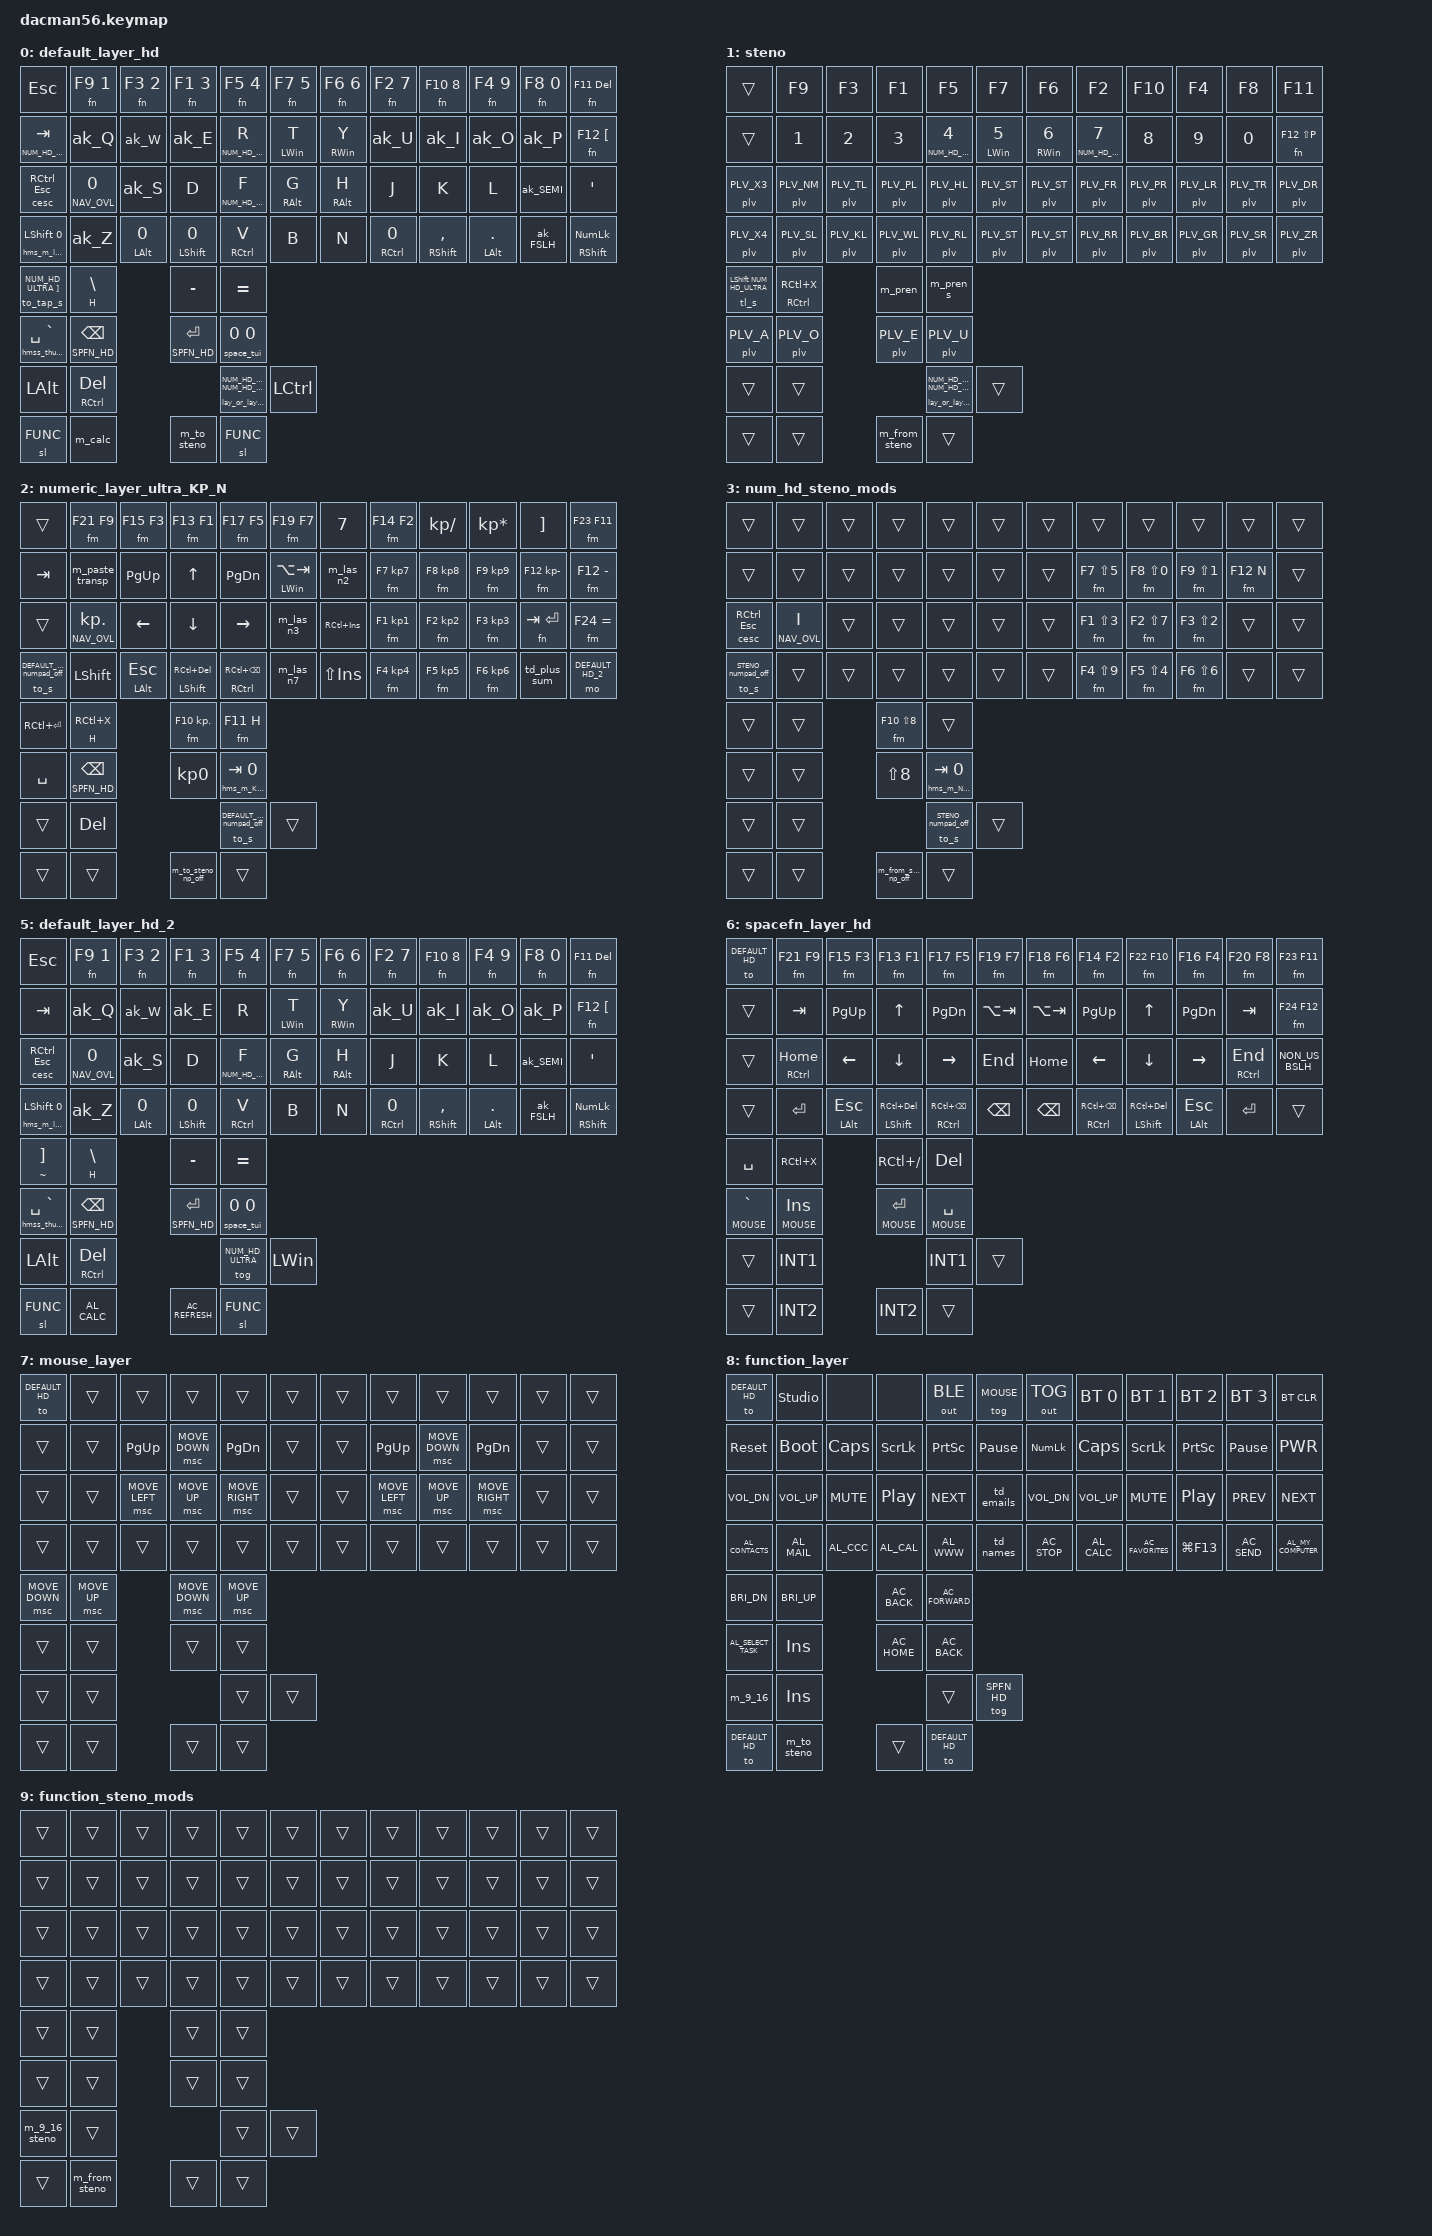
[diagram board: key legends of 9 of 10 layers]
#include <behaviors.dtsi>
#include <dt-bindings/zmk/keys.h>
#include <dt-bindings/zmk/bt.h>
#include <dt-bindings/zmk/outputs.h>
#include <dt-bindings/zmk/hid-io/plover_hid.h>
#include <dt-bindings/zmk/pointing.h>

#define steno_on F17
#define steno_off LC(F17)
#define numpad_on F18
#define numpad_off LC(F18)

#define DEFAULT_HD 0
#define STENO 1
#define NUM_HD_ULTRA 2
#define NUM_HD_STENO_MODS 3
#define NAV_OVL 4
#define DEFAULT_HD_2 5
#define SPFN_HD 6
#define MOUSE 7
#define FUNC 8
#define FUNC_STENO_MODS 9

#include "combos.dtsi"
#include "behaviors.dtsi"
#include "macros.dtsi"
#include "adaptive.dtsi"

/ {
	conditional_layers {
		compatible = "zmk,conditional-layers";

		num_hd_steno {
			if-layers = <STENO NUM_HD_ULTRA>;
			then-layer = <NUM_HD_STENO_MODS>;
		};

		function_steno {
			if-layers = <STENO FUNC>;
			then-layer = <FUNC_STENO_MODS>;
		};
	};
};

/ {
	keymap {
		compatible = "zmk,keymap";

		default_layer_hd {
			bindings = <
				&kp ESC                  &fn F9 N1                &fn F3 N2                &fn F1 N3                &fn F5 N4                &fn F7 N5                &fn F6 N6                &fn F2 N7                &fn F10 N8               &fn F4 N9                &fn F8 N0                &fn F11 DEL
				&lt_s NUM_HD_ULTRA TAB   &ak_Q                    &ak_W                    &ak_E                    &lt_s_tap NUM_HD_ULTRA R &hmss LWIN T             &hmss RWIN Y             &ak_U                    &ak_I                    &ak_O                    &ak_P                    &fn F12 LBKT
				&cesc RCTRL ESC          &hms_m_a NAV_OVL 0       &ak_S                    &kp D                    &lt_s NUM_HD_ULTRA F     &hms RALT G              &hms RALT H              &kp J                    &kp K                    &kp L                    &ak_SEMI                 &kp SQT
				&hms_m_lsrs LSHFT 0      &ak_Z                    &hms_m_x LALT 0          &hm_m_c LSHFT 0          &hmms RCTRL V            &kp B                    &kp N                    &hms_m_m RCTRL 0         &hmf RSHFT COMMA         &hmms LALT DOT           &ak_FSLH                 &hms RSHFT KP_NUM
				&to_tap_s NUM_HD_ULTRA RBKT &hm H BSLH                                      &kp MINUS                &kp EQUAL
				&hmss_thumb SPACE GRAVE  &lts SPFN_HD BSPC                               &lts SPFN_HD ENTER      &space_tui 0 0
				&kp LALT                 &hms RCTL DEL                                   &lay_or_lay_s_num NUM_HD_ULTRA NUM_HD_ULTRA &kp LCTL
				&sl FUNC                 &m_calc                                         &m_to_steno              &sl FUNC
			>;
		};

		steno {
			bindings = <
				&trans                   &kp F9                   &kp F3                   &kp F1                   &kp F5                   &kp F7                   &kp F6                   &kp F2                   &kp F10                  &kp F4                   &kp F8                   &kp F11
				&trans                   &kp N1                   &kp N2                   &kp N3                   &lt_s NUM_HD_ULTRA N4    &hmss LWIN N5            &hmss RWIN N6            &lt_s NUM_HD_ULTRA N7    &kp N8                   &kp N9                   &kp N0                   &fn F12 LS(P)
				&plv PLV_X3              &plv PLV_NM              &plv PLV_TL              &plv PLV_PL              &plv PLV_HL              &plv PLV_ST              &plv PLV_ST              &plv PLV_FR              &plv PLV_PR              &plv PLV_LR              &plv PLV_TR              &plv PLV_DR
				&plv PLV_X4              &plv PLV_SL              &plv PLV_KL              &plv PLV_WL              &plv PLV_RL              &plv PLV_ST              &plv PLV_ST              &plv PLV_RR              &plv PLV_BR              &plv PLV_GR              &plv PLV_SR              &plv PLV_ZR
				&tl_s LSHFT NUM_HD_ULTRA &hmms RCTRL RC(X)                               &m_pren                  &m_pren_s
				&plv PLV_A             &plv PLV_O                                      &plv PLV_E              &plv PLV_U
				&trans                 &trans                                          &lay_or_lay_s_num NUM_HD_ULTRA NUM_HD_ULTRA &trans
				&trans                 &trans                                          &m_from_steno           &trans
			>;
		};

		numeric_layer_ultra_KP_N {
			bindings = <
				&trans                   &fm F21 F9               &fm F15 F3               &fm F13 F1               &fm F17 F5               &fm F19 F7               &kp N7                   &fm F14 F2               &kp KP_DIVIDE            &kp KP_MULTIPLY          &kp RBKT                 &fm F23 F11
				&kp TAB                  &m_paste_transp          &kp PG_UP                &kp UP                   &kp PG_DN                &hmss LWIN LA(TAB)       &m_las_n2                &fm F7 KP_N7             &fm F8 KP_N8             &fm F9 KP_N9             &fm F12 KP_MINUS         &fm F12 MINUS
				&trans                   &lts_tp NAV_OVL KP_DOT   &kp LEFT                 &kp DOWN                 &kp RIGHT                &m_las_n3                &kp RC(INS)              &fm F1 KP_N1             &fm F2 KP_N2             &fm F3 KP_N3             &fn TAB ENTER            &fm F24 EQUAL
				&to_s DEFAULT_HD numpad_off &kp LSHFT              &hms LALT ESC            &hms LSHFT RC(DEL)       &hms RCTRL RC(BSPC)      &m_las_n7                &kp LS(INS)              &fm F4 KP_N4             &fm F5 KP_N5             &fm F6 KP_N6             &td_plus_sum             &mo DEFAULT_HD_2
				&kp RC(ENTER)          &hm H RC(X)                                     &fm F10 KP_DOT           &fm F11 H
				&kp SPACE              &lts SPFN_HD BSPC                               &kp KP_N0               &hms_m_KP_N00 TAB 0
				&trans                 &kp DEL                                         &to_s DEFAULT_HD numpad_off &trans
				&trans                 &trans                                          &m_to_steno_np_off      &trans
			>;
		};

		num_hd_steno_mods {
			bindings = <
				&trans                   &trans                   &trans                   &trans                   &trans                   &trans                   &trans                   &trans                   &trans                   &trans                   &trans                   &trans
				&trans                   &trans                   &trans                   &trans                   &trans                   &trans                   &trans                   &fm F7 LS(N5)            &fm F8 LS(N0)            &fm F9 LS(N1)            &fm F12 N                &trans
				&cesc RCTRL ESC          &lts NAV_OVL I           &trans                   &trans                   &trans                   &trans                   &trans                   &fm F1 LS(N3)            &fm F2 LS(N7)            &fm F3 LS(N2)            &trans                   &trans
				&to_s STENO numpad_off   &trans                   &trans                   &trans                   &trans                   &trans                   &trans                   &fm F4 LS(N9)            &fm F5 LS(N4)            &fm F6 LS(N6)            &trans                   &trans
				&trans                   &trans                                          &fm F10 LS(N8)           &trans
				&trans                 &trans                                          &kp LS(N8)              &hms_m_N88 TAB 0
				&trans                 &trans                                          &to_s STENO numpad_off  &trans
				&trans                 &trans                                          &m_from_steno_np_off    &trans
			>;
		};

		nav_overlay_layer {
			bindings = <
				&trans                   &trans                   &trans                   &trans                   &trans                   &trans                   &trans                   &trans                   &trans                   &trans                   &trans                   &trans
				&trans                   &trans                   &kp LA(PG_UP)            &kp RC(UP)               &kp LA(PG_DN)            &kp LS(LA(TAB))          &trans                   &trans                   &trans                   &trans                   &trans                   &trans
				&trans                   &trans                   &kp RC(LEFT)             &kp RC(DOWN)             &kp RC(RIGHT)            &trans                   &trans                   &trans                   &trans                   &trans                   &trans                   &trans                   &trans
				&trans                   &trans                   &trans                   &trans                   &trans                   &trans                   &trans                   &trans                   &trans                   &trans                   &trans                   &trans
				&trans                   &trans                                          &trans                   &trans
				&trans                 &trans                                          &trans                  &trans
				&trans                 &trans                                          &trans                  &trans
				&trans                 &trans                                          &trans                  &trans
			>;
		};

		default_layer_hd_2 {
			bindings = <
				&kp ESC                  &fn F9 N1                &fn F3 N2                &fn F1 N3                &fn F5 N4                &fn F7 N5                &fn F6 N6                &fn F2 N7                &fn F10 N8               &fn F4 N9                &fn F8 N0                &fn F11 DEL
				&kp TAB                  &ak_Q                    &ak_W                    &ak_E                    &kp R                    &hmss LWIN T             &hmss RWIN Y             &ak_U                    &ak_I                    &ak_O                    &ak_P                    &fn F12 LBKT
				&cesc RCTRL ESC          &hms_m_a NAV_OVL 0       &ak_S                    &kp D                    &lt NUM_HD_ULTRA F       &hms RALT G              &hms RALT H              &kp J                    &kp K                    &kp L                    &ak_SEMI                 &kp SQT
				&hms_m_lsrs LSHFT 0      &ak_Z                    &hms_m_x LALT 0          &hm_m_c LSHFT 0          &hmms RCTRL V            &kp B                    &kp N                    &hms_m_m RCTRL 0         &hmf RSHFT COMMA         &hmms LALT DOT           &ak_FSLH                 &hms RSHFT KP_NUM
				&hm TILDE RBKT          &hm H BSLH                                      &kp MINUS                &kp EQUAL
				&hmss_thumb SPACE GRAVE &lts SPFN_HD BSPC                               &lts SPFN_HD ENTER      &space_tui 0 0
				&kp LALT               &hms RCTL DEL                                   &tog NUM_HD_ULTRA       &kp LWIN
				&sl FUNC                &kp C_AL_CALC                                   &kp C_AC_REFRESH        &sl FUNC
			>;
		};

		spacefn_layer_hd {
			bindings = <
				&to DEFAULT_HD           &fm F21 F9               &fm F15 F3               &fm F13 F1               &fm F17 F5               &fm F19 F7               &fm F18 F6               &fm F14 F2               &fm F22 F10              &fm F16 F4               &fm F20 F8               &fm F23 F11
				&trans                   &kp TAB                  &kp PG_UP                &kp UP                   &kp PG_DN                &kp LA(TAB)              &kp LA(TAB)              &kp PG_UP                &kp UP                   &kp PG_DN                &kp TAB                  &fm F24 F12
				&trans                   &hm RCTRL HOME           &kp LEFT                 &kp DOWN                 &kp RIGHT                &kp END                  &kp HOME                 &kp LEFT                 &kp DOWN                 &kp RIGHT                &hm RCTRL END            &kp NON_US_BSLH
				&trans                   &kp ENTER                &hms LALT ESC            &hm LSHFT RC(DEL)        &hms RCTRL RC(BSPC)      &kp BSPC                 &kp BSPC                 &hms RCTRL RC(BSPC)      &hm LSHFT RC(DEL)        &hms LALT ESC            &kp ENTER                &trans
				&kp SPACE                &kp RC(X)                                       &kp RC(FSLH)             &kp DEL
				&lts MOUSE GRAVE         &lts MOUSE INS                                  &lts MOUSE ENTER        &lts MOUSE SPACE
				&trans                 &kp INT1                                        &kp INT1                &trans
				&trans                 &kp INT2                                        &kp INT2                &trans
			>;
		};

		mouse_layer {
			bindings = <
				&to DEFAULT_HD           &trans                   &trans                   &trans                   &trans                   &trans                   &trans                   &trans                   &trans                   &trans                   &trans                   &trans
				&trans                   &trans                   &kp PG_UP                &msc MOVE_DOWN           &kp PG_DN                &trans                   &trans                   &kp PG_UP                &msc MOVE_DOWN           &kp PG_DN                &trans                   &trans
				&trans                   &trans                   &msc MOVE_LEFT           &msc MOVE_UP             &msc MOVE_RIGHT          &trans                   &trans                   &msc MOVE_LEFT           &msc MOVE_UP             &msc MOVE_RIGHT          &trans                   &trans
				&trans                   &trans                   &trans                   &trans                   &trans                   &trans                   &trans                   &trans                   &trans                   &trans                   &trans                   &trans
				&msc MOVE_DOWN           &msc MOVE_UP                                    &msc MOVE_DOWN           &msc MOVE_UP
				&trans                 &trans                                          &trans                  &trans
				&trans                 &trans                                          &trans                  &trans
				&trans                 &trans                                          &trans                  &trans
			>;
		};

		function_layer {
			bindings = <
				&to DEFAULT_HD           &studio_unlock           &none                    &none                    &out OUT_BLE             &tog MOUSE               &out OUT_TOG             &bt BT_SEL 0             &bt BT_SEL 1             &bt BT_SEL 2             &bt BT_SEL 3             &bt BT_CLR
				&sys_reset               &bootloader              &kp CAPS                 &kp SLCK                 &kp PSCRN                &kp PAUSE_BREAK          &kp KP_NUM               &kp CAPS                 &kp SLCK                 &kp PSCRN                &kp PAUSE_BREAK          &kp K_PWR
				&kp C_VOL_DN             &kp C_VOL_UP             &kp C_MUTE               &kp C_PP                 &kp C_NEXT               &td_emails               &kp C_VOL_DN             &kp C_VOL_UP             &kp C_MUTE               &kp C_PP                 &kp C_PREV               &kp C_NEXT
				&kp C_AL_CONTACTS        &kp C_AL_MAIL            &kp C_AL_CCC             &kp C_AL_CAL             &kp C_AL_WWW             &td_names                &kp C_AC_STOP            &kp C_AL_CALC            &kp C_AC_FAVORITES       &kp LG(F13)              &kp C_AC_SEND            &kp C_AL_MY_COMPUTER
				&kp C_BRI_DN             &kp C_BRI_UP                                     &kp C_AC_BACK            &kp C_AC_FORWARD
				&kp C_AL_SELECT_TASK     &kp INS                                          &kp C_AC_HOME           &kp C_AC_BACK
				&m_9_16                 &kp INS                                          &trans                   &tog SPFN_HD
				&to DEFAULT_HD           &m_to_steno                                      &trans                   &to DEFAULT_HD
			>;
		};

		function_steno_mods {
			bindings = <
				&trans                   &trans                   &trans                   &trans                   &trans                   &trans                   &trans                   &trans                   &trans                   &trans                   &trans                   &trans
				&trans                   &trans                   &trans                   &trans                   &trans                   &trans                   &trans                   &trans                   &trans                   &trans                   &trans                   &trans
				&trans                   &trans                   &trans                   &trans                   &trans                   &trans                   &trans                   &trans                   &trans                   &trans                   &trans                   &trans
				&trans                   &trans                   &trans                   &trans                   &trans                   &trans                   &trans                   &trans                   &trans                   &trans                   &trans                   &trans
				&trans                   &trans                                          &trans                   &trans
				&trans                 &trans                                          &trans                  &trans
				&m_9_16_steno          &trans                                          &trans                  &trans
				&trans                 &m_from_steno                                   &trans                  &trans
			>;
		};
	};
};
